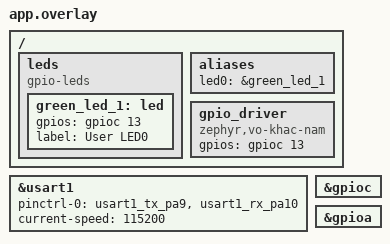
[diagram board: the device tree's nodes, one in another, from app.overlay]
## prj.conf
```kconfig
# CONFIG_APPLICATION_DEFINED_SYSCALL=y
# CONFIG_GREETINGS_DRIVER=y
# CONFIG_SAMPLE_GPIO_DRIVER=y
CONFIG_GPIO=y
```

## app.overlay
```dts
/ {
    leds {
        compatible = "gpio-leds";

        green_led_1: led {
            gpios = <&gpioc 13 GPIO_ACTIVE_HIGH>;
            label = "User LED0";
        };
    };

    aliases {
        led0 = &green_led_1;
    };


    gpio_driver: gpio_driver{
        compatible = "zephyr,vo-khac-nam";
        gpios = <&gpioc 13 GPIO_ACTIVE_HIGH>;
        status ="okay";
    };

    };

&usart1 {
        pinctrl-0 = <&usart1_tx_pa9 &usart1_rx_pa10>;
        pinctrl-names = "default";
        current-speed = <115200>;
        status = "okay";
    };

&gpioc {
    status = "okay";
};
&gpioa {
    status = "okay";
};
```

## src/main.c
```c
#include <zephyr/device.h>
#include <gpio_driver.h>
#include <zephyr/kernel.h>

#include <zephyr/logging/log.h>
LOG_MODULE_REGISTER(main, LOG_LEVEL_DBG);
static const struct gpio_dt_spec led = GPIO_DT_SPEC_GET(DT_NODELABEL(gpio_driver),gpios);
int main(void)
{
    // const struct device *gpio;

    // LOG_INF("Example greetings driver");

    // gpio = DEVICE_DT_GET(DT_NODELABEL(gpio_driver));
    // if (!device_is_ready(gpio_driver)) {
    //     LOG_ERR("Greetings not ready");
    //     return 0;
    // }
    while(1){
    k_msleep(3000);
    toggle_pin(&led);
    LOG_INF("Example greetings driver");
    }
    return 0;
}
```
